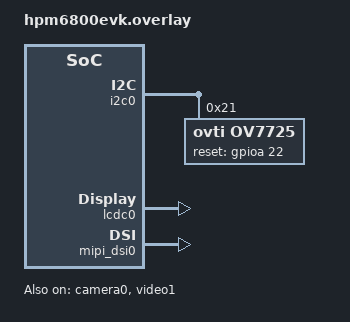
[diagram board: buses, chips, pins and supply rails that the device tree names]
/*
 * Copyright 2024 HPMicro
 * SPDX-License-Identifier: Apache-2.0
 */

/ {
    chosen {
        zephyr,display = &panel_mc10128007;
        zephyr,camera = &video1;
    };
};

&adc0 {
	status = "disabled";
};


&i2c0 {
	status = "okay";
	pinctrl-0 = <&pinmux_i2c0>;
	pinctrl-names = "default";

	ov7725: ov7725@21 {
		compatible = "ovti,ov7725";
		reg = <0x21>;
		status = "okay";

		reset-gpios = <&gpioa 22 GPIO_ACTIVE_HIGH>;
	};

};

&camera0 {
	status = "okay";
	interface = "dvp";
	pinctrl-0 = <&pinmux_dvp0>;
	pinctrl-names = "default";
	pixclk_sampling_falling = <0>;
	hsync_active_low = <1>;
	vsync_active_low = <1>;
};

&video1 {
	status = "okay";
	video_count = <1>;
	sensor = <&ov7725>;
	camera = <&camera0>;
};

&lcdc0 {
	status = "okay";
};

&mipi_dsi0 {
	status = "okay";
};

&panel_mc10128007 {
	status = "okay";
	pixel-format = <PANEL_PIXEL_FORMAT_RGB_565>;
};
